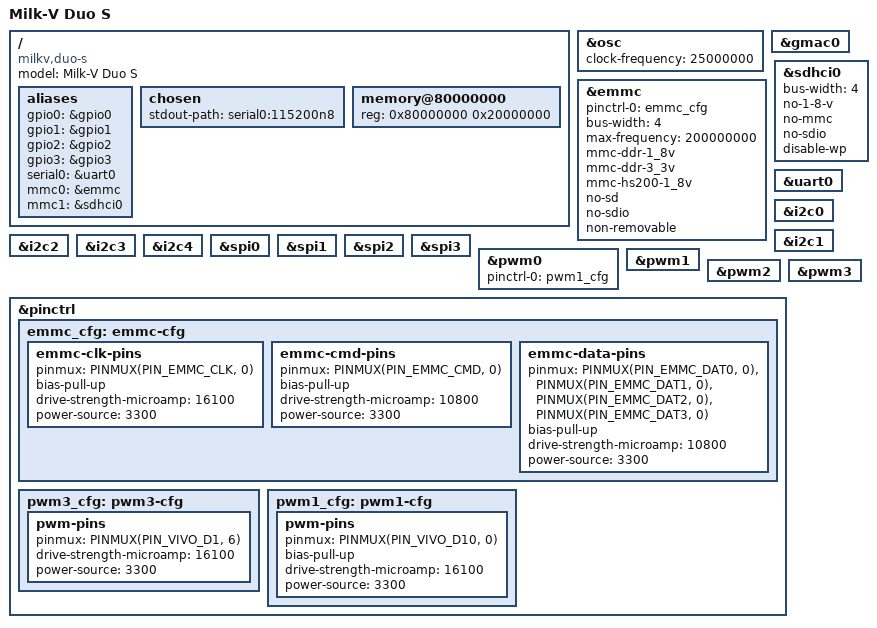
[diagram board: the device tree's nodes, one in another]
// SPDX-License-Identifier: (GPL-2.0 OR MIT)
/*
 * Copyright (C) 2024 Michael Opdenacker <michael.opdenacker@bootlin.com>
 */

/dts-v1/;

#include "cv1812h.dtsi"

/ {
	model = "Milk-V Duo S";
	compatible = "milkv,duo-s", "sophgo,cv1812h";

	aliases {
		gpio0 = &gpio0;
		gpio1 = &gpio1;
		gpio2 = &gpio2;
		gpio3 = &gpio3;
		serial0 = &uart0;
		mmc0 = &emmc;
		mmc1 = &sdhci0;
	};

	chosen {
		stdout-path = "serial0:115200n8";
	};

	memory@80000000 {
		reg = <0x80000000 0x20000000>;
	};
};

&osc {
	clock-frequency = <25000000>;
};

&gmac0 {
	status = "okay";
};

&emmc {
	pinctrl-0 = <&emmc_cfg>;
	pinctrl-names = "default";
	status = "okay";
	bus-width = <4>;
	max-frequency = <200000000>;
	mmc-ddr-1_8v;
	mmc-ddr-3_3v;
	mmc-hs200-1_8v;
	no-sd;
	no-sdio;
	non-removable;
};

&sdhci0 {
	status = "okay";
	bus-width = <4>;
	no-1-8-v;
	no-mmc;
	no-sdio;
	disable-wp;
};

&uart0 {
	status = "okay";
};

&i2c0 {
	status = "okay";
};

&i2c1 {
	status = "okay";
};

&i2c2 {
	status = "okay";
};

&i2c3 {
	status = "okay";
};

&i2c4 {
	status = "okay";
};

&spi0 {
	status = "okay";
};

&spi1 {
	status = "okay";
};

&spi2 {
	status = "okay";
};

&spi3 {
	status = "okay";
};

&pwm0 {
        status = "okay";
	pinctrl-0 = <&pwm1_cfg>;
	pinctrl-names = "default";
};

&pwm1 {
        status = "okay";
};

&pwm2 {
        status = "okay";
};

&pwm3 {
	status = "okay";
};

&pinctrl {
	emmc_cfg: emmc-cfg {
		emmc-clk-pins {
			pinmux = <PINMUX(PIN_EMMC_CLK, 0)>;
			bias-pull-up;
			drive-strength-microamp = <16100>;
			power-source = <3300>;
		};

		emmc-cmd-pins {
			pinmux = <PINMUX(PIN_EMMC_CMD, 0)>;
			bias-pull-up;
			drive-strength-microamp = <10800>;
			power-source = <3300>;
		};

		emmc-data-pins {
			pinmux = <PINMUX(PIN_EMMC_DAT0, 0)>,
				 <PINMUX(PIN_EMMC_DAT1, 0)>,
				 <PINMUX(PIN_EMMC_DAT2, 0)>,
				 <PINMUX(PIN_EMMC_DAT3, 0)>;
			bias-pull-up;
			drive-strength-microamp = <10800>;
			power-source = <3300>;
		};
	};

	pwm3_cfg: pwm3-cfg {
		pwm-pins {
			pinmux = <PINMUX(PIN_VIVO_D1, 6)>;
			// bias-pull-up;
			drive-strength-microamp = <16100>;
			power-source = <3300>;
		};
	};
	pwm1_cfg: pwm1-cfg {
		pwm-pins {
			pinmux = <PINMUX(PIN_VIVO_D10, 0)>;
			bias-pull-up;
			drive-strength-microamp = <16100>;
			power-source = <3300>;
		};
	};
	
};
